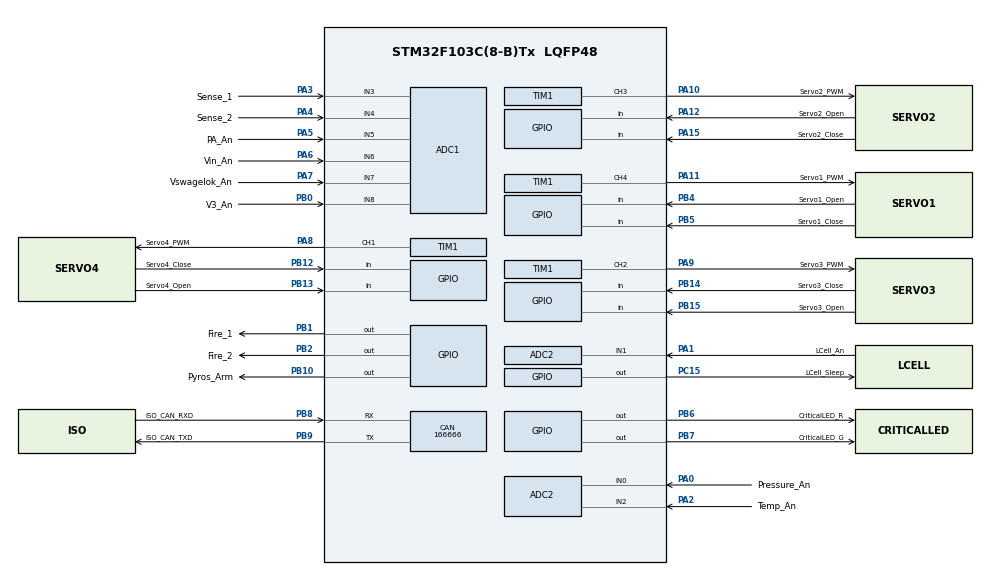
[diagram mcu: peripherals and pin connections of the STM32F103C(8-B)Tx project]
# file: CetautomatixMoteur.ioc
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ADC1.Channel-4\#ChannelRegularConversion=ADC_CHANNEL_3
ADC1.Channel-5\#ChannelRegularConversion=ADC_CHANNEL_4
ADC1.Channel-6\#ChannelRegularConversion=ADC_CHANNEL_5
ADC1.Channel-7\#ChannelRegularConversion=ADC_CHANNEL_6
ADC1.Channel-8\#ChannelRegularConversion=ADC_CHANNEL_7
ADC1.Channel-9\#ChannelRegularConversion=ADC_CHANNEL_8
ADC1.ExternalTrigConv=ADC_EXTERNALTRIGCONV_T3_TRGO
ADC1.NbrOfConversion=6
ADC1.NbrOfConversionFlag=1
ADC1.Rank-4\#ChannelRegularConversion=1
ADC1.Rank-5\#ChannelRegularConversion=2
ADC1.Rank-6\#ChannelRegularConversion=3
ADC1.Rank-7\#ChannelRegularConversion=4
ADC1.Rank-8\#ChannelRegularConversion=5
ADC1.Rank-9\#ChannelRegularConversion=6
ADC1.SamplingTime-4\#ChannelRegularConversion=ADC_SAMPLETIME_71CYCLES_5
ADC1.SamplingTime-5\#ChannelRegularConversion=ADC_SAMPLETIME_71CYCLES_5
ADC1.SamplingTime-6\#ChannelRegularConversion=ADC_SAMPLETIME_71CYCLES_5
ADC1.SamplingTime-7\#ChannelRegularConversion=ADC_SAMPLETIME_71CYCLES_5
ADC1.SamplingTime-8\#ChannelRegularConversion=ADC_SAMPLETIME_71CYCLES_5
ADC1.SamplingTime-9\#ChannelRegularConversion=ADC_SAMPLETIME_71CYCLES_5
ADC1.master=1
ADC2.Channel-0\#ChannelRegularConversion=ADC_CHANNEL_0
ADC2.Channel-1\#ChannelRegularConversion=ADC_CHANNEL_1
ADC2.Channel-2\#ChannelRegularConversion=ADC_CHANNEL_2
ADC2.ExternalTrigConv=ADC_EXTERNALTRIGCONV_T3_TRGO
ADC2.NbrOfConversion=3
ADC2.NbrOfConversionFlag=1
ADC2.Rank-0\#ChannelRegularConversion=1
ADC2.Rank-1\#ChannelRegularConversion=2
ADC2.Rank-2\#ChannelRegularConversion=3
ADC2.SamplingTime-0\#ChannelRegularConversion=ADC_SAMPLETIME_71CYCLES_5
ADC2.SamplingTime-1\#ChannelRegularConversion=ADC_SAMPLETIME_71CYCLES_5
ADC2.SamplingTime-2\#ChannelRegularConversion=ADC_SAMPLETIME_71CYCLES_5
CAN.CalculateBaudRate=166666
CAN.CalculateTimeBit=6000
CAN.CalculateTimeQuantum=2000.0
Dma.ADC1.0.Direction=DMA_PERIPH_TO_MEMORY
Dma.ADC1.0.Instance=DMA1_Channel1
Dma.ADC1.0.MemDataAlignment=DMA_MDATAALIGN_HALFWORD
Dma.ADC1.0.MemInc=DMA_MINC_ENABLE
Dma.ADC1.0.Mode=DMA_CIRCULAR
Dma.ADC1.0.PeriphDataAlignment=DMA_PDATAALIGN_HALFWORD
Dma.ADC1.0.PeriphInc=DMA_PINC_DISABLE
Dma.ADC1.0.Priority=DMA_PRIORITY_MEDIUM
Dma.Request0=ADC1
Mcu.Family=STM32F1
Mcu.Name=STM32F103C(8-B)Tx
Mcu.Package=LQFP48
NVIC.DMA1_Channel1_IRQn=true\:0\:0\:false\:false\:true\:false\:true\:true
NVIC.PriorityGroup=NVIC_PRIORITYGROUP_4
PA0-WKUP.GPIO_Label=Pressure_An
PA0-WKUP.Signal=ADCx_IN0
PA1.GPIO_Label=LCell_An
PA1.Signal=ADCx_IN1
PA10.GPIO_Label=Servo2_PWM
PA10.Signal=S_TIM1_CH3
PA11.GPIO_Label=Servo1_PWM
PA11.Signal=S_TIM1_CH4
PA12.GPIO_Label=Servo2_Open
PA12.Signal=GPIO_Input
PA13.GPIO_Label=SYS_SWDIO
PA13.Mode=Trace_Asynchronous_SW
PA13.Signal=SYS_JTMS-SWDIO
PA14.GPIO_Label=SYS_SWCLK
PA14.Mode=Trace_Asynchronous_SW
PA14.Signal=SYS_JTCK-SWCLK
PA15.GPIO_Label=Servo2_Close
PA15.Signal=GPIO_Input
PA2.GPIO_Label=Temp_An
PA2.Signal=ADCx_IN2
PA3.GPIO_Label=Sense_1
PA3.Signal=ADCx_IN3
PA4.GPIO_Label=Sense_2
PA4.Signal=ADCx_IN4
PA5.GPIO_Label=PA_An
PA5.Signal=ADCx_IN5
PA6.GPIO_Label=Vin_An
PA6.Signal=ADCx_IN6
PA7.GPIO_Label=Vswagelok_An
PA7.Signal=ADCx_IN7
PA8.GPIO_Label=Servo4_PWM
PA8.Signal=S_TIM1_CH1
PA9.GPIO_Label=Servo3_PWM
PA9.Signal=S_TIM1_CH2
PB0.GPIO_Label=V3_An
PB0.Signal=ADCx_IN8
PB1.GPIO_Label=Fire_1
PB1.Signal=GPIO_Output
PB10.GPIO_Label=Pyros_Arm
PB10.Signal=GPIO_Output
PB12.GPIO_Label=Servo4_Close
PB12.Signal=GPIO_Input
PB13.GPIO_Label=Servo4_Open
PB13.Signal=GPIO_Input
PB14.GPIO_Label=Servo3_Close
PB14.Signal=GPIO_Input
PB15.GPIO_Label=Servo3_Open
PB15.Signal=GPIO_Input
PB2.GPIO_Label=Fire_2
PB2.Signal=GPIO_Output
PB3.GPIO_Label=SYS_SWO
PB3.Mode=Trace_Asynchronous_SW
PB3.Signal=SYS_JTDO-TRACESWO
PB4.GPIO_Label=Servo1_Open
PB4.Signal=GPIO_Input
PB5.GPIO_Label=Servo1_Close
PB5.Signal=GPIO_Input
PB6.GPIO_Label=CriticalLED_R
PB6.Signal=GPIO_Output
PB7.GPIO_Label=CriticalLED_G
PB7.Signal=GPIO_Output
PB8.GPIO_Label=ISO_CAN_RXD
PB8.Mode=CAN_Activate
PB8.Signal=CAN_RX
PB9.GPIO_Label=ISO_CAN_TXD
PB9.Mode=CAN_Activate
PB9.Signal=CAN_TX
PC15-OSC32_OUT.GPIO_Label=LCell_Sleep
PC15-OSC32_OUT.Signal=GPIO_Output
PD0-OSC_IN.GPIO_Label=OSC_IN
PD0-OSC_IN.Mode=HSE-External-Oscillator
PD0-OSC_IN.Signal=RCC_OSC_IN
PD1-OSC_OUT.GPIO_Label=OSC_OUT
PD1-OSC_OUT.Mode=HSE-External-Oscillator
PD1-OSC_OUT.Signal=RCC_OSC_OUT
ProjectManager.HeapSize=0x200
ProjectManager.StackSize=0x400
ProjectManager.TargetToolchain=STM32CubeIDE
RCC.APB1Freq_Value=8000000
RCC.APB2Freq_Value=8000000
SH.ADCx_IN0.0=ADC2_IN0,IN0
SH.ADCx_IN1.0=ADC2_IN1,IN1
SH.ADCx_IN2.0=ADC2_IN2,IN2
SH.ADCx_IN3.0=ADC1_IN3,IN3
SH.ADCx_IN4.0=ADC1_IN4,IN4
SH.ADCx_IN5.0=ADC1_IN5,IN5
SH.ADCx_IN6.0=ADC1_IN6,IN6
SH.ADCx_IN7.0=ADC1_IN7,IN7
SH.ADCx_IN8.0=ADC1_IN8,IN8
SH.S_TIM1_CH1.0=TIM1_CH1,PWM Generation1 CH1
SH.S_TIM1_CH2.0=TIM1_CH2,PWM Generation2 CH2
SH.S_TIM1_CH3.0=TIM1_CH3,PWM Generation3 CH3
SH.S_TIM1_CH4.0=TIM1_CH4,PWM Generation4 CH4
TIM1.Channel-PWM\ Generation1\ CH1=TIM_CHANNEL_1
TIM1.Channel-PWM\ Generation2\ CH2=TIM_CHANNEL_2
TIM1.Channel-PWM\ Generation3\ CH3=TIM_CHANNEL_3
TIM1.Channel-PWM\ Generation4\ CH4=TIM_CHANNEL_4
VP_CRC_VS_CRC.Mode=CRC_Activate
VP_TIM1_VS_ClockSourceINT.Mode=Internal
board=custom

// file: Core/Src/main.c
/* USER CODE BEGIN Header */
/**
  ******************************************************************************
  * @file           : main.c
  * @brief          : Main program body
  ******************************************************************************
  * @attention
  *
  * Copyright (c) 2026 STMicroelectronics.
  * All rights reserved.
  *
  * This software is licensed under terms that can be found in the LICENSE file
  * in the root directory of this software component.
  * If no LICENSE file comes with this software, it is provided AS-IS.
  *
  ******************************************************************************
  */
/* USER CODE END Header */
#include "main.h"

/* USER CODE BEGIN Includes */
// ajout des fihcier de configuration TAG-CAN
#include "../Inc/tag_can_system/config_value.h"
#include "../Inc/tag_can_system/gestion_tag.h"
#include "../Inc/tag_can_system/sub_include/data_container.h"
#include "../Inc/tag_can_system/sub_include/tag_manager.h"

/* USER CODE END Includes */

ADC_HandleTypeDef hadc1;
ADC_HandleTypeDef hadc2;
DMA_HandleTypeDef hdma_adc1;

CAN_HandleTypeDef hcan;

CRC_HandleTypeDef hcrc;

TIM_HandleTypeDef htim1;

/* USER CODE BEGIN PV */
CAN_TxHeaderTypeDef TxHeader_moteur;
CAN_RxHeaderTypeDef RxHeader_moteur;
uint8_t RxData[8];
extern uint8_t TxData[8];
int32_t TxMailbox;
/* USER CODE END PV */

void SystemClock_Config(void);
static void MX_GPIO_Init(void);
static void MX_DMA_Init(void);
static void MX_ADC1_Init(void);
static void MX_ADC2_Init(void);
static void MX_CAN_Init(void);
static void MX_CRC_Init(void);
static void MX_TIM1_Init(void);

int main(void)
{

  /* MCU Configuration--------------------------------------------------------*/

  /* Reset of all peripherals, Initializes the Flash interface and the Systick. */
  HAL_Init();

  /* USER CODE BEGIN Init */
  // setup CAN tag
  setup_TCANS();
  /* USER CODE END Init */

  /* Configure the system clock */
  SystemClock_Config();

  /* Initialize all configured peripherals */
  MX_GPIO_Init();
  MX_DMA_Init();
  MX_ADC1_Init();
  MX_ADC2_Init();
  MX_CAN_Init();
  MX_CRC_Init();
  MX_TIM1_Init();

  /* Infinite loop */
  while (1)
  {

	  // ### ------ update des valeur------

	  // start the trensmission
	  if(HAL_CAN_AddTxMessage(&hcan, &TxHeader_moteur, TxData, &TxMailbox) != HAL_OK){
		  /*trensmission de l'erreur*/
		  Error_Handler();
	  }

  }
}

void SystemClock_Config(void)
{
  RCC_OscInitTypeDef RCC_OscInitStruct = {0};
  RCC_ClkInitTypeDef RCC_ClkInitStruct = {0};
  RCC_PeriphCLKInitTypeDef PeriphClkInit = {0};

  /** Initializes the RCC Oscillators according to the specified parameters
  * in the RCC_OscInitTypeDef structure.
  */
  RCC_OscInitStruct.OscillatorType = RCC_OSCILLATORTYPE_HSI;
  RCC_OscInitStruct.HSIState = RCC_HSI_ON;
  RCC_OscInitStruct.HSICalibrationValue = RCC_HSICALIBRATION_DEFAULT;
  RCC_OscInitStruct.PLL.PLLState = RCC_PLL_NONE;
  if (HAL_RCC_OscConfig(&RCC_OscInitStruct) != HAL_OK)
  {
    Error_Handler();
  }

  /** Initializes the CPU, AHB and APB buses clocks
  */
  RCC_ClkInitStruct.ClockType = RCC_CLOCKTYPE_HCLK|RCC_CLOCKTYPE_SYSCLK
                              |RCC_CLOCKTYPE_PCLK1|RCC_CLOCKTYPE_PCLK2;
  RCC_ClkInitStruct.SYSCLKSource = RCC_SYSCLKSOURCE_HSI;
  RCC_ClkInitStruct.AHBCLKDivider = RCC_SYSCLK_DIV1;
  RCC_ClkInitStruct.APB1CLKDivider = RCC_HCLK_DIV1;
  RCC_ClkInitStruct.APB2CLKDivider = RCC_HCLK_DIV1;

  if (HAL_RCC_ClockConfig(&RCC_ClkInitStruct, FLASH_LATENCY_0) != HAL_OK)
  {
    Error_Handler();
  }
  PeriphClkInit.PeriphClockSelection = RCC_PERIPHCLK_ADC;
  PeriphClkInit.AdcClockSelection = RCC_ADCPCLK2_DIV2;
  if (HAL_RCCEx_PeriphCLKConfig(&PeriphClkInit) != HAL_OK)
  {
    Error_Handler();
  }
}

static void MX_ADC1_Init(void)
{

  ADC_ChannelConfTypeDef sConfig = {0};

  /** Common config
  */
  hadc1.Instance = ADC1;
  hadc1.Init.ScanConvMode = ADC_SCAN_ENABLE;
  hadc1.Init.ContinuousConvMode = DISABLE;
  hadc1.Init.DiscontinuousConvMode = DISABLE;
  hadc1.Init.ExternalTrigConv = ADC_EXTERNALTRIGCONV_T3_TRGO;
  hadc1.Init.DataAlign = ADC_DATAALIGN_RIGHT;
  hadc1.Init.NbrOfConversion = 5;
  if (HAL_ADC_Init(&hadc1) != HAL_OK)
  {
    Error_Handler();
  }

  /** Configure Regular Channel
  */
  sConfig.Channel = ADC_CHANNEL_3;
  sConfig.Rank = ADC_REGULAR_RANK_1;
  sConfig.SamplingTime = ADC_SAMPLETIME_71CYCLES_5;
  if (HAL_ADC_ConfigChannel(&hadc1, &sConfig) != HAL_OK)
  {
    Error_Handler();
  }

  /** Configure Regular Channel
  */
  sConfig.Channel = ADC_CHANNEL_4;
  sConfig.Rank = ADC_REGULAR_RANK_2;
  if (HAL_ADC_ConfigChannel(&hadc1, &sConfig) != HAL_OK)
  {
    Error_Handler();
  }

  /** Configure Regular Channel
  */
  sConfig.Channel = ADC_CHANNEL_5;
  sConfig.Rank = ADC_REGULAR_RANK_3;
  if (HAL_ADC_ConfigChannel(&hadc1, &sConfig) != HAL_OK)
  {
    Error_Handler();
  }

  /** Configure Regular Channel
  */
  sConfig.Channel = ADC_CHANNEL_6;
  sConfig.Rank = ADC_REGULAR_RANK_4;
  if (HAL_ADC_ConfigChannel(&hadc1, &sConfig) != HAL_OK)
  {
    Error_Handler();
  }

  /** Configure Regular Channel
  */
  sConfig.Channel = ADC_CHANNEL_7;
  sConfig.Rank = ADC_REGULAR_RANK_5;
  if (HAL_ADC_ConfigChannel(&hadc1, &sConfig) != HAL_OK)
  {
    Error_Handler();
  }

}

static void MX_ADC2_Init(void)
{

  ADC_ChannelConfTypeDef sConfig = {0};

  /** Common config
  */
  hadc2.Instance = ADC2;
  hadc2.Init.ScanConvMode = ADC_SCAN_ENABLE;
  hadc2.Init.ContinuousConvMode = DISABLE;
  hadc2.Init.DiscontinuousConvMode = DISABLE;
  hadc2.Init.ExternalTrigConv = ADC_EXTERNALTRIGCONV_T3_TRGO;
  hadc2.Init.DataAlign = ADC_DATAALIGN_RIGHT;
  hadc2.Init.NbrOfConversion = 3;
  if (HAL_ADC_Init(&hadc2) != HAL_OK)
  {
    Error_Handler();
  }

  /** Configure Regular Channel
  */
  sConfig.Channel = ADC_CHANNEL_0;
  sConfig.Rank = ADC_REGULAR_RANK_1;
  sConfig.SamplingTime = ADC_SAMPLETIME_71CYCLES_5;
  if (HAL_ADC_ConfigChannel(&hadc2, &sConfig) != HAL_OK)
  {
    Error_Handler();
  }

  /** Configure Regular Channel
  */
  sConfig.Channel = ADC_CHANNEL_1;
  sConfig.Rank = ADC_REGULAR_RANK_2;
  if (HAL_ADC_ConfigChannel(&hadc2, &sConfig) != HAL_OK)
  {
    Error_Handler();
  }

  /** Configure Regular Channel
  */
  sConfig.Channel = ADC_CHANNEL_2;
  sConfig.Rank = ADC_REGULAR_RANK_3;
  if (HAL_ADC_ConfigChannel(&hadc2, &sConfig) != HAL_OK)
  {
    Error_Handler();
  }

}

static void MX_CAN_Init(void)
{

  hcan.Instance = CAN1;
  hcan.Init.Prescaler = 16;
  hcan.Init.Mode = CAN_MODE_NORMAL;
  hcan.Init.SyncJumpWidth = CAN_SJW_1TQ;
  hcan.Init.TimeSeg1 = CAN_BS1_1TQ;
  hcan.Init.TimeSeg2 = CAN_BS2_1TQ;
  hcan.Init.TimeTriggeredMode = DISABLE;
  hcan.Init.AutoBusOff = DISABLE;
  hcan.Init.AutoWakeUp = DISABLE;
  hcan.Init.AutoRetransmission = DISABLE;
  hcan.Init.ReceiveFifoLocked = DISABLE;
  hcan.Init.TransmitFifoPriority = DISABLE;
  if (HAL_CAN_Init(&hcan) != HAL_OK)
  {
    Error_Handler();
  }

}

static void MX_CRC_Init(void)
{

  hcrc.Instance = CRC;
  if (HAL_CRC_Init(&hcrc) != HAL_OK)
  {
    Error_Handler();
  }

}

static void MX_TIM1_Init(void)
{

  TIM_ClockConfigTypeDef sClockSourceConfig = {0};
  TIM_MasterConfigTypeDef sMasterConfig = {0};
  TIM_OC_InitTypeDef sConfigOC = {0};
  TIM_BreakDeadTimeConfigTypeDef sBreakDeadTimeConfig = {0};

  htim1.Instance = TIM1;
  htim1.Init.Prescaler = 0;
  htim1.Init.CounterMode = TIM_COUNTERMODE_UP;
  htim1.Init.Period = 65535;
  htim1.Init.ClockDivision = TIM_CLOCKDIVISION_DIV1;
  htim1.Init.RepetitionCounter = 0;
  htim1.Init.AutoReloadPreload = TIM_AUTORELOAD_PRELOAD_DISABLE;
  if (HAL_TIM_Base_Init(&htim1) != HAL_OK)
  {
    Error_Handler();
  }
  sClockSourceConfig.ClockSource = TIM_CLOCKSOURCE_INTERNAL;
  if (HAL_TIM_ConfigClockSource(&htim1, &sClockSourceConfig) != HAL_OK)
  {
    Error_Handler();
  }
  if (HAL_TIM_PWM_Init(&htim1) != HAL_OK)
  {
    Error_Handler();
  }
  sMasterConfig.MasterOutputTrigger = TIM_TRGO_RESET;
  sMasterConfig.MasterSlaveMode = TIM_MASTERSLAVEMODE_DISABLE;
  if (HAL_TIMEx_MasterConfigSynchronization(&htim1, &sMasterConfig) != HAL_OK)
  {
    Error_Handler();
  }
  sConfigOC.OCMode = TIM_OCMODE_PWM1;
  sConfigOC.Pulse = 0;
  sConfigOC.OCPolarity = TIM_OCPOLARITY_HIGH;
  sConfigOC.OCNPolarity = TIM_OCNPOLARITY_HIGH;
  sConfigOC.OCFastMode = TIM_OCFAST_DISABLE;
  sConfigOC.OCIdleState = TIM_OCIDLESTATE_RESET;
  sConfigOC.OCNIdleState = TIM_OCNIDLESTATE_RESET;
  if (HAL_TIM_PWM_ConfigChannel(&htim1, &sConfigOC, TIM_CHANNEL_1) != HAL_OK)
  {
    Error_Handler();
  }
  if (HAL_TIM_PWM_ConfigChannel(&htim1, &sConfigOC, TIM_CHANNEL_2) != HAL_OK)
  {
    Error_Handler();
  }
  if (HAL_TIM_PWM_ConfigChannel(&htim1, &sConfigOC, TIM_CHANNEL_3) != HAL_OK)
  {
    Error_Handler();
  }
  if (HAL_TIM_PWM_ConfigChannel(&htim1, &sConfigOC, TIM_CHANNEL_4) != HAL_OK)
  {
    Error_Handler();
  }
  sBreakDeadTimeConfig.OffStateRunMode = TIM_OSSR_DISABLE;
  sBreakDeadTimeConfig.OffStateIDLEMode = TIM_OSSI_DISABLE;
  sBreakDeadTimeConfig.LockLevel = TIM_LOCKLEVEL_OFF;
  sBreakDeadTimeConfig.DeadTime = 0;
  sBreakDeadTimeConfig.BreakState = TIM_BREAK_DISABLE;
  sBreakDeadTimeConfig.BreakPolarity = TIM_BREAKPOLARITY_HIGH;
  sBreakDeadTimeConfig.AutomaticOutput = TIM_AUTOMATICOUTPUT_DISABLE;
  if (HAL_TIMEx_ConfigBreakDeadTime(&htim1, &sBreakDeadTimeConfig) != HAL_OK)
  {
    Error_Handler();
  }
  HAL_TIM_MspPostInit(&htim1);

}

static void MX_DMA_Init(void)
{

  /* DMA controller clock enable */
  __HAL_RCC_DMA1_CLK_ENABLE();

  /* DMA interrupt init */
  /* DMA1_Channel1_IRQn interrupt configuration */
  HAL_NVIC_SetPriority(DMA1_Channel1_IRQn, 0, 0);
  HAL_NVIC_EnableIRQ(DMA1_Channel1_IRQn);

}

static void MX_GPIO_Init(void)
{
  GPIO_InitTypeDef GPIO_InitStruct = {0};

  /* GPIO Ports Clock Enable */
  __HAL_RCC_GPIOC_CLK_ENABLE();
  __HAL_RCC_GPIOD_CLK_ENABLE();
  __HAL_RCC_GPIOA_CLK_ENABLE();
  __HAL_RCC_GPIOB_CLK_ENABLE();

  /*Configure GPIO pin Output Level */
  HAL_GPIO_WritePin(GPIOC, Pressure_Sleep_Pin|LCell_Sleep_Pin, GPIO_PIN_RESET);

  /*Configure GPIO pin Output Level */
  HAL_GPIO_WritePin(GPIOB, Fire_1_Pin|Fire_2_Pin|Pyros_Arm_Pin|CriticalLED_G_Pin
                          |CriticalLED_R_Pin, GPIO_PIN_RESET);

  /*Configure GPIO pins : Pressure_Sleep_Pin LCell_Sleep_Pin */
  GPIO_InitStruct.Pin = Pressure_Sleep_Pin|LCell_Sleep_Pin;
  GPIO_InitStruct.Mode = GPIO_MODE_OUTPUT_PP;
  GPIO_InitStruct.Pull = GPIO_NOPULL;
  GPIO_InitStruct.Speed = GPIO_SPEED_FREQ_LOW;
  HAL_GPIO_Init(GPIOC, &GPIO_InitStruct);

  /*Configure GPIO pins : Fire_1_Pin Fire_2_Pin Pyros_Arm_Pin CriticalLED_G_Pin
                           CriticalLED_R_Pin */
  GPIO_InitStruct.Pin = Fire_1_Pin|Fire_2_Pin|Pyros_Arm_Pin|CriticalLED_G_Pin
                          |CriticalLED_R_Pin;
  GPIO_InitStruct.Mode = GPIO_MODE_OUTPUT_PP;
  GPIO_InitStruct.Pull = GPIO_NOPULL;
  GPIO_InitStruct.Speed = GPIO_SPEED_FREQ_LOW;
  HAL_GPIO_Init(GPIOB, &GPIO_InitStruct);

  /*Configure GPIO pins : Servo4_Close_Pin Servo4_Open_Pin Servo3_Close_Pin Servo3_Open_Pin
                           Servo1_Open_Pin Servo1_Close_Pin */
  GPIO_InitStruct.Pin = Servo4_Close_Pin|Servo4_Open_Pin|Servo3_Close_Pin|Servo3_Open_Pin
                          |Servo1_Open_Pin|Servo1_Close_Pin;
  GPIO_InitStruct.Mode = GPIO_MODE_INPUT;
  GPIO_InitStruct.Pull = GPIO_NOPULL;
  HAL_GPIO_Init(GPIOB, &GPIO_InitStruct);

  /*Configure GPIO pins : Servo2_Open_Pin Servo2_Close_Pin */
  GPIO_InitStruct.Pin = Servo2_Open_Pin|Servo2_Close_Pin;
  GPIO_InitStruct.Mode = GPIO_MODE_INPUT;
  GPIO_InitStruct.Pull = GPIO_NOPULL;
  HAL_GPIO_Init(GPIOA, &GPIO_InitStruct);

}

/* USER CODE BEGIN 4 */

static void CAN_Config_Filter(void){
	/*suposed to be the second init of CAN*/
	/*## - 2- configure the CAN Filter ####################*/
	CAN_FilterTypeDef sFilterConfig;
	// no filter configured for now
}

/**
  * @brief  Rx Fifo 0 message pending callback
  * @param  hcan: pointer to a CAN_HandleTypeDef structure that contains
  *         the configuration information for the specified CAN.
  * @retval None
  */

void HAL_CAN_RxFifo0MsgPendingCallback(CAN_HandleTypeDef *hcan_){
	/*Obtenir le message RX*/
	if(HAL_CAN_GetRxMessage(hcan_, CAN_RX_FIFO0, &RxHeader_moteur, RxData) != HAL_OK){
		/*erreur de reception*/
		Error_Handler();
	}

}

void setup_TCANS(void){
	// reset the container and the tags
	init_data_container();
	init_tag_manager();

	// ------------------------ définisser ici les tags -----------------------
	// exemple:
	set_tag("SEQ", 3);
	set_tag("HB", 1);
	set_tag("CI", 2);
	set_tag("ALIM_BATERIE", 7);
	set_tag("EDC", 4);
	set_tag("N20PS", 16);
	set_tag("TLC", 12);
	set_tag("N20DVS",1);
	set_tag("N20IV",1);
	set_tag("N20MV",1);
	set_tag("Timestamp", 16);

}

/* USER CODE END 4 */

void Error_Handler(void)
{
  __disable_irq();
  while (1)
  {
  }
}
